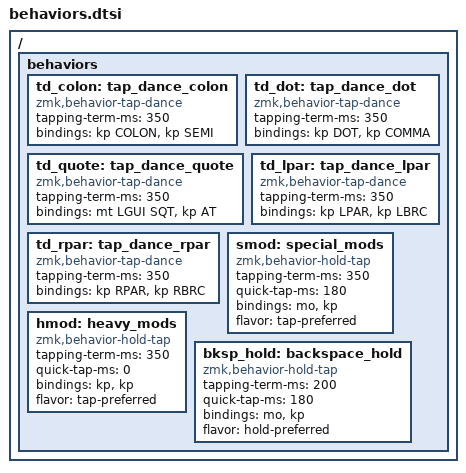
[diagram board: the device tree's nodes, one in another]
#include <behaviors.dtsi>
#include <dt-bindings/zmk/keys.h>
#include <dt-bindings/zmk/bt.h>

/{
    behaviors {
        td_colon: tap_dance_colon {
            compatible = "zmk,behavior-tap-dance";
            #binding-cells = <0>;
            tapping-term-ms = <350>;
            bindings = <&kp COLON>, <&kp SEMI>;
        };
        td_dot: tap_dance_dot {
            compatible = "zmk,behavior-tap-dance";
            #binding-cells = <0>;
            tapping-term-ms = <350>;
            bindings = <&kp DOT>, <&kp COMMA>;
        };
        td_quote: tap_dance_quote {
            compatible = "zmk,behavior-tap-dance";
            #binding-cells = <0>;
            tapping-term-ms = <350>;
            bindings = <&mt LGUI SQT>, <&kp AT>;
        };
        td_lpar: tap_dance_lpar {
            compatible = "zmk,behavior-tap-dance";
            #binding-cells = <0>;
            tapping-term-ms = <350>;
            bindings = <&kp LPAR>, <&kp LBRC>;
        };
        td_rpar: tap_dance_rpar {
            compatible = "zmk,behavior-tap-dance";
            #binding-cells = <0>;
            tapping-term-ms = <350>;
            bindings = <&kp RPAR>, <&kp RBRC>;
        };
        
        smod: special_mods {
            compatible = "zmk,behavior-hold-tap";
            #binding-cells = <2>;
            tapping-term-ms = <350>;
            quick-tap-ms = <180>;
            bindings = <&mo>, <&kp>;
            flavor = "tap-preferred";
        };
        hmod: heavy_mods {
            compatible = "zmk,behavior-hold-tap";
            #binding-cells = <2>;
            tapping-term-ms = <350>;
            quick-tap-ms = <0>;
            bindings = <&kp>, <&kp>;
            flavor = "tap-preferred";
        };
        bksp_hold: backspace_hold {
            compatible = "zmk,behavior-hold-tap";
            #binding-cells = <2>;
            tapping-term-ms = <200>;
            quick-tap-ms = <180>;
            bindings = <&mo>, <&kp>;
            flavor = "hold-preferred";
        };
    };
};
